VERSION ""

NS_ :

BS_:

BU_: OffBoardDiagnosticTool1 Modine_TMC

BO_ 3221225472 VECTOR__INDEPENDENT_SIG_MSG: 0 Vector__XXX
 SG_ speedLim_batt_in_temp_low : 0|16@1+ (1,0) [0|65535] "RPM" Vector__XXX

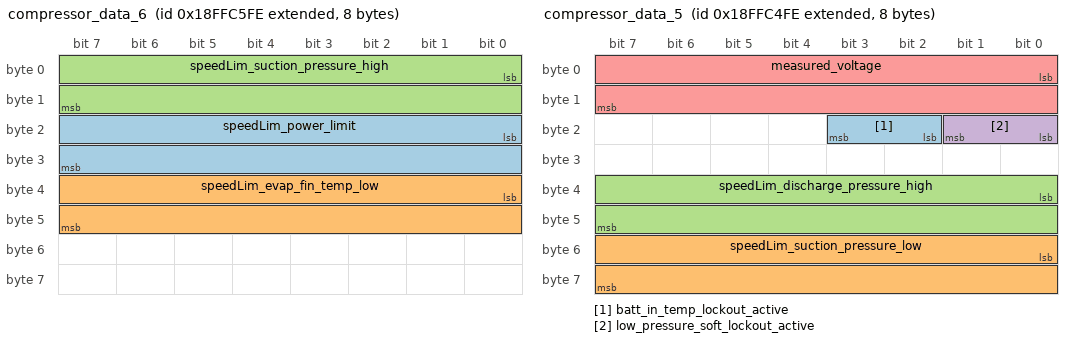
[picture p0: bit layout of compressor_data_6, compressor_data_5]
BO_ 2566899198 compressor_data_6: 8 Vector__XXX
 SG_ speedLim_power_limit : 16|16@1+ (1,0) [0|65535] "RPM" Vector__XXX
 SG_ speedLim_evap_fin_temp_low : 32|16@1+ (1,0) [0|65535] "RPM" Vector__XXX
 SG_ speedLim_suction_pressure_high : 0|16@1+ (1,0) [0|65535] "RPM" Vector__XXX

BO_ 2566898942 compressor_data_5: 8 Vector__XXX
 SG_ batt_in_temp_lockout_active : 18|2@1+ (1,0) [0|3] "" Vector__XXX
 SG_ speedLim_suction_pressure_low : 48|16@1+ (1,0) [0|65535] "RPM" Vector__XXX
 SG_ speedLim_discharge_pressure_high : 32|16@1+ (1,0) [0|65535] "RPM" Vector__XXX
 SG_ low_pressure_soft_lockout_active : 16|2@1+ (1,0) [0|3] "" Vector__XXX
 SG_ measured_voltage : 0|16@1+ (0.05,0) [0|3276.75] "V" Vector__XXX

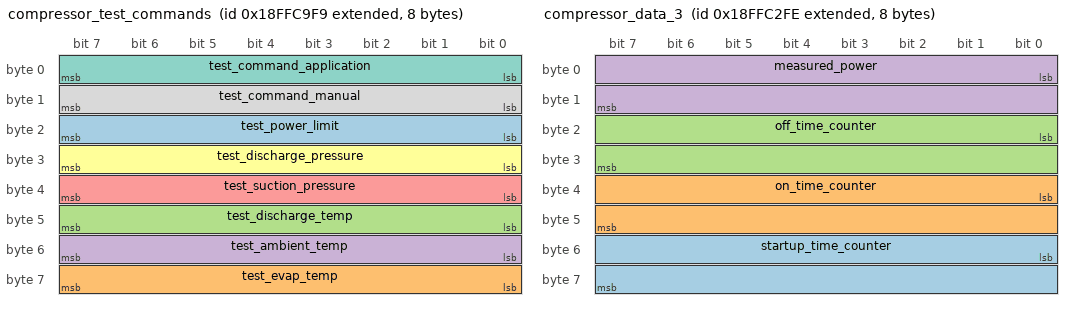
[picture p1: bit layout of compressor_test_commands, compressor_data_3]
BO_ 2566900217 compressor_test_commands: 8 OffBoardDiagnosticTool1
 SG_ test_power_limit : 16|8@1+ (100,0) [0|25500] "W" Vector__XXX
 SG_ test_evap_temp : 56|8@1+ (1,-40) [-40|215] "deg_C" Vector__XXX
 SG_ test_discharge_temp : 40|8@1+ (1,-40) [-40|215] "deg_C" Vector__XXX
 SG_ test_ambient_temp : 48|8@1+ (1,-40) [-40|215] "deg_C" Vector__XXX
 SG_ test_suction_pressure : 32|8@1+ (16,0) [0|4080] "kPa-a" Vector__XXX
 SG_ test_discharge_pressure : 24|8@1+ (16,0) [0|4080] "kPa-a" Vector__XXX
 SG_ test_command_application : 0|8@1+ (100,0) [0|25500] "RPM" Vector__XXX
 SG_ test_command_manual : 8|8@1+ (100,0) [0|25500] "RPM" Vector__XXX

BO_ 2566898686 compressor_data_4: 8 Vector__XXX
 SG_ manual_command_enabled : 26|2@1+ (1,0) [0|3] "" Vector__XXX
 SG_ compressor_state : 28|4@1+ (1,0) [0|15] "" Vector__XXX
 SG_ lockout_cycle_count : 56|8@1+ (1,0) [0|255] "" Vector__XXX
 SG_ discharge_temp_lockout_count : 48|8@1+ (1,0) [0|255] "" Vector__XXX
 SG_ low_pressure_hard_lockout_count : 40|8@1+ (1,0) [0|255] "" Vector__XXX
 SG_ high_pressure_lockout_count : 32|8@1+ (1,0) [0|255] "" Vector__XXX
 SG_ permament_lockout_active : 24|2@1+ (1,0) [0|3] "" Vector__XXX
 SG_ lockout_cycle_latch : 22|2@1+ (1,0) [0|3] "" Vector__XXX
 SG_ lockout_cycle_active : 20|2@1+ (1,0) [0|3] "" Vector__XXX
 SG_ general_fault_active : 18|2@1+ (1,0) [0|3] "" Vector__XXX
 SG_ speed_fault_active : 16|2@1+ (1,0) [0|3] "" Vector__XXX
 SG_ low_ambient_temp_lockout_active : 14|2@1+ (1,0) [0|3] "" Vector__XXX
 SG_ evap_temperature_lockout_active : 12|2@1+ (1,0) [0|3] "" Vector__XXX
 SG_ discharge_temp_lockout_active : 10|2@1+ (1,0) [0|3] "" Vector__XXX
 SG_ low_pressure_hard_lockout_active : 8|2@1+ (1,0) [0|3] "" Vector__XXX
 SG_ high_pressure_lockout_active : 6|2@1+ (1,0) [0|3] "" Vector__XXX
 SG_ startup_sequence_complete : 4|2@1+ (1,0) [0|3] "" Vector__XXX
 SG_ on_time_complete : 2|2@1+ (1,0) [0|3] "" Vector__XXX
 SG_ off_time_complete : 0|2@1+ (1,0) [0|3] "" Vector__XXX

BO_ 2566898430 compressor_data_3: 8 Vector__XXX
 SG_ startup_time_counter : 48|16@1+ (0.1,0) [0|65535] "s" Vector__XXX
 SG_ on_time_counter : 32|16@1+ (0.1,0) [0|65535] "s" Vector__XXX
 SG_ off_time_counter : 16|16@1+ (0.1,0) [0|65535] "s" Vector__XXX
 SG_ measured_power : 0|16@1+ (1,0) [0|65535] "W" Vector__XXX

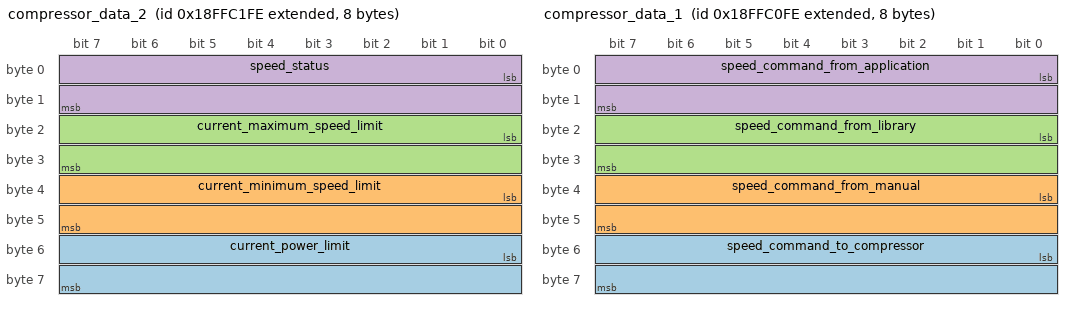
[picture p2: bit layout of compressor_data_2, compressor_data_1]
BO_ 2566898174 compressor_data_2: 8 Vector__XXX
 SG_ current_power_limit : 48|16@1+ (1,0) [0|65535] "W" Vector__XXX
 SG_ current_minimum_speed_limit : 32|16@1+ (1,0) [0|65535] "RPM" Vector__XXX
 SG_ current_maximum_speed_limit : 16|16@1+ (1,0) [0|65535] "RPM" Vector__XXX
 SG_ speed_status : 0|16@1+ (1,0) [0|65535] "RPM" Vector__XXX

BO_ 2566897918 compressor_data_1: 8 Vector__XXX
 SG_ speed_command_to_compressor : 48|16@1+ (1,0) [0|65535] "RPM" Vector__XXX
 SG_ speed_command_from_manual : 32|16@1+ (1,0) [0|65535] "RPM" Vector__XXX
 SG_ speed_command_from_library : 16|16@1+ (1,0) [0|65535] "RPM" Vector__XXX
 SG_ speed_command_from_application : 0|16@1+ (1,0) [0|65535] "RPM" Vector__XXX

CM_ "V1.4.0 - Add new enumeration to startup state machine
V1.3.0 ZJF 5/14/2023 - Add speed limit values from all 5 foldbacks 
";
CM_ BO_ 3221225472 "This is a message for not used signals, created by Vector CANdb++ DBC OLE DB Provider.";
CM_ SG_ 2566898686 low_pressure_hard_lockout_count "count of low_pressure_hard_lockout occurances";
CM_ SG_ 2566898686 low_pressure_hard_lockout_active "This occurs when pressure dips below the low_pressure_soft_lockout threshold. This would typically indicate no charge or low charge";
BA_DEF_ SG_  "J1939SLOT" STRING ;
BA_DEF_  "BaudRate" STRING ;
BA_DEF_  "DatabaseVersionDate" STRING ;
BA_DEF_  "DatabaseVersion" STRING ;
BA_DEF_ SG_  "SigType" ENUM  "Default","Range","RangeSigned","ASCII","Discrete","Control","ReferencePGN","DTC","StringDelimiter","StringLength","StringLengthControl","MessageCounter","MessageChecksum";
BA_DEF_ SG_  "GenSigEVName" STRING ;
BA_DEF_ SG_  "GenSigILSupport" ENUM  "No","Yes";
BA_DEF_ SG_  "GenSigSendType" ENUM  "Cyclic","OnWrite","OnWriteWithRepetition","OnChange","OnChangeWithRepetition","IfActive","IfActiveWithRepetition","NoSigSendType";
BA_DEF_ SG_  "GenSigStartValue" INT 0 2147483647;
BA_DEF_ BO_  "GenMsgILSupport" ENUM  "No","Yes";
BA_DEF_ BU_  "NmStationAddress" INT 0 255;
BA_DEF_ BO_  "GenMsgSendType" ENUM  "cyclic","NotUsed","IfActive","NotUsed","NotUsed","NotUsed","NotUsed","NotUsed","noMsgSendType";
BA_DEF_ BO_  "GenMsgRequestable" INT 0 1;
BA_DEF_  "DBName" STRING ;
BA_DEF_  "BusType" STRING ;
BA_DEF_  "ProtocolType" STRING ;
BA_DEF_ BO_  "VFrameFormat" ENUM  "StandardCAN","ExtendedCAN","reserved","J1939PG";
BA_DEF_DEF_  "J1939SLOT" "-";
BA_DEF_DEF_  "BaudRate" "500K";
BA_DEF_DEF_  "DatabaseVersionDate" "1-March-2022";
BA_DEF_DEF_  "DatabaseVersion" "";
BA_DEF_DEF_  "SigType" "Default";
BA_DEF_DEF_  "GenSigEVName" "Env@Nodename_@Signame";
BA_DEF_DEF_  "GenSigILSupport" "Yes";
BA_DEF_DEF_  "GenSigSendType" "NoSigSendType";
BA_DEF_DEF_  "GenSigStartValue" 0;
BA_DEF_DEF_  "GenMsgILSupport" "Yes";
BA_DEF_DEF_  "NmStationAddress" 254;
BA_DEF_DEF_  "GenMsgSendType" "noMsgSendType";
BA_DEF_DEF_  "GenMsgRequestable" 1;
BA_DEF_DEF_  "DBName" "";
BA_DEF_DEF_  "BusType" "CAN";
BA_DEF_DEF_  "ProtocolType" "J1939";
BA_DEF_DEF_  "VFrameFormat" "J1939PG";
BA_ "DatabaseVersionDate" "20-May-2024";
BA_ "DatabaseVersion" "1.4.0";
BA_ "BaudRate" "<any>";
BA_ "DBName" "compressor_library";
BA_ "NmStationAddress" BU_ OffBoardDiagnosticTool1 249;
BA_ "GenSigStartValue" SG_ 2566900217 test_evap_temp 40;
BA_ "GenSigStartValue" SG_ 2566900217 test_discharge_temp 40;
BA_ "GenSigStartValue" SG_ 2566900217 test_ambient_temp 40;
VAL_ 2566898686 compressor_state 5 "wait to start" 4 "wait to stop" 3 "normal run" 2 "startup sequence - comp. start" 1 "startup sequence - fan only" 0 "off - ready to start" ;
